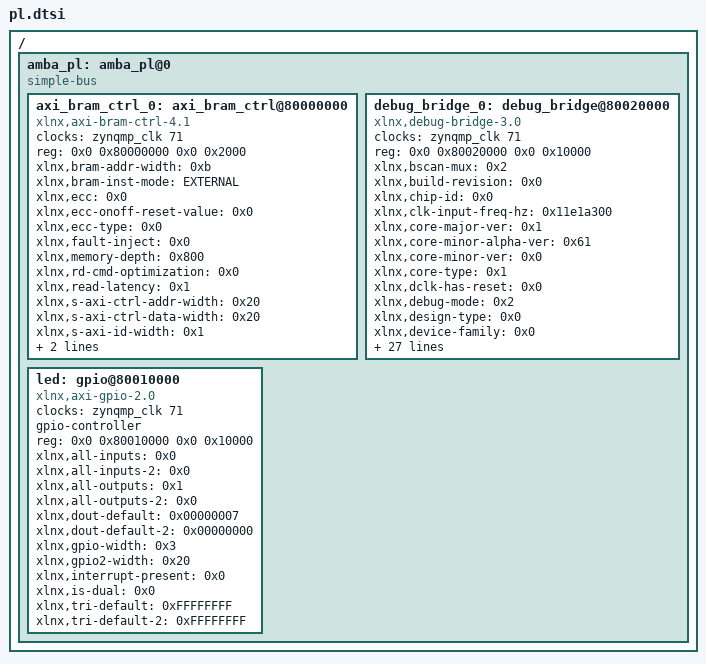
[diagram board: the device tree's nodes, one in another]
/*
 * CAUTION: This file is automatically generated by Xilinx.
 * Version:  
 * Today is: Tue Nov 30 13:30:24 2021
 */


/ {
	amba_pl: amba_pl@0 {
		#address-cells = <2>;
		#size-cells = <2>;
		compatible = "simple-bus";
		ranges ;
		axi_bram_ctrl_0: axi_bram_ctrl@80000000 {
			clock-names = "s_axi_aclk";
			clocks = <&zynqmp_clk 71>;
			compatible = "xlnx,axi-bram-ctrl-4.1";
			reg = <0x0 0x80000000 0x0 0x2000>;
			xlnx,bram-addr-width = <0xb>;
			xlnx,bram-inst-mode = "EXTERNAL";
			xlnx,ecc = <0x0>;
			xlnx,ecc-onoff-reset-value = <0x0>;
			xlnx,ecc-type = <0x0>;
			xlnx,fault-inject = <0x0>;
			xlnx,memory-depth = <0x800>;
			xlnx,rd-cmd-optimization = <0x0>;
			xlnx,read-latency = <0x1>;
			xlnx,s-axi-ctrl-addr-width = <0x20>;
			xlnx,s-axi-ctrl-data-width = <0x20>;
			xlnx,s-axi-id-width = <0x1>;
			xlnx,s-axi-supports-narrow-burst = <0x0>;
			xlnx,single-port-bram = <0x0>;
		};
		debug_bridge_0: debug_bridge@80020000 {
			clock-names = "s_axi_aclk";
			clocks = <&zynqmp_clk 71>;
			compatible = "xlnx,debug-bridge-3.0", "generic-uio";
			reg = <0x0 0x80020000 0x0 0x10000>;
			xlnx,bscan-mux = <0x2>;
			xlnx,build-revision = <0x0>;
			xlnx,chip-id = <0x0>;
			xlnx,clk-input-freq-hz = <0x11e1a300>;
			xlnx,core-major-ver = <0x1>;
			xlnx,core-minor-alpha-ver = <0x61>;
			xlnx,core-minor-ver = <0x0>;
			xlnx,core-type = <0x1>;
			xlnx,dclk-has-reset = <0x0>;
			xlnx,debug-mode = <0x2>;
			xlnx,design-type = <0x0>;
			xlnx,device-family = <0x0>;
			xlnx,en-bscanid-vec = "false";
			xlnx,en-int-sim = <0x1>;
			xlnx,en-passthrough = <0x0>;
			xlnx,enable-clk-divider = "false";
			xlnx,fifo-style = "SUBCORE";
			xlnx,ir-id-instr = <0x0>;
			xlnx,ir-user1-instr = <0x0>;
			xlnx,ir-width = <0x0>;
			xlnx,major-version = <0xe>;
			xlnx,master-intf-type = <0x1>;
			xlnx,minor-version = <0x1>;
			xlnx,num-bs-master = <0x1>;
			xlnx,pcie-ext-cfg-base-addr = <0x400>;
			xlnx,pcie-ext-cfg-next-ptr = <0x000>;
			xlnx,pcie-ext-cfg-vsec-id = <0x0008>;
			xlnx,pcie-ext-cfg-vsec-length = <0x020>;
			xlnx,pcie-ext-cfg-vsec-rev-id = <0x0>;
			xlnx,tck-clock-ratio = <0x8>;
			xlnx,two-prim-mode = "false";
			xlnx,use-bufr = <0x0>;
			xlnx,use-ext-bscan = "true";
			xlnx,use-softbscan = <0x1>;
			xlnx,use-startup-clk = "false";
			xlnx,user-scan-chain = <0x1>;
			xlnx,xsdb-num-slaves = <0x0>;
			xlnx,xvc-hw-id = <0x0002>;
			xlnx,xvc-sw-id = <0x0001>;
		};
		led: gpio@80010000 {
			#gpio-cells = <3>;
			clock-names = "s_axi_aclk";
			clocks = <&zynqmp_clk 71>;
			compatible = "xlnx,axi-gpio-2.0", "xlnx,xps-gpio-1.00.a";
			gpio-controller ;
			reg = <0x0 0x80010000 0x0 0x10000>;
			xlnx,all-inputs = <0x0>;
			xlnx,all-inputs-2 = <0x0>;
			xlnx,all-outputs = <0x1>;
			xlnx,all-outputs-2 = <0x0>;
			xlnx,dout-default = <0x00000007>;
			xlnx,dout-default-2 = <0x00000000>;
			xlnx,gpio-width = <0x3>;
			xlnx,gpio2-width = <0x20>;
			xlnx,interrupt-present = <0x0>;
			xlnx,is-dual = <0x0>;
			xlnx,tri-default = <0xFFFFFFFF>;
			xlnx,tri-default-2 = <0xFFFFFFFF>;
		};
	};
};
